# ATA5787 device description
Architecture: AVR8; Family: megaAVR
Registers are 8-bit, access not given, no defined reset value unless marked. A register's access mark holds for its fields unless they carry their own. Offsets are from the block's base; [hi:lo] are bit positions; {n}, {i} and the like mark numbered series.

## TIMER3
Instances: TIMER3 0x00
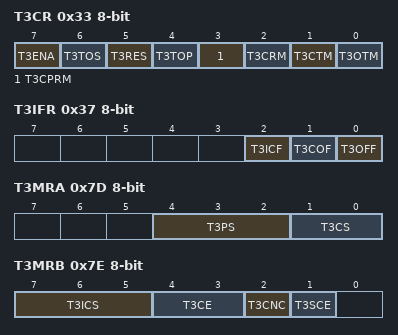
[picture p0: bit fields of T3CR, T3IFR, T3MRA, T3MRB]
0x33 T3CR — Timer3 Control Register
  [7] T3ENA — Timer3 Enable
  [6] T3TOS — Timer3 Toggle with Start
  [5] T3RES — Timer3 Reset
  [4] T3TOP — Timer3 Toggle Output Preset
  [3] T3CPRM — Timer3 Capture Reset Mask
  [2] T3CRM — Timer3 Compare Reset Mask
  [1] T3CTM — Timer3 Compare Toggle Mask
  [0] T3OTM — Timer3 Overflow Toggle Mask
0x37 T3IFR — Timer3 Interrupt Flag Register
  [2] T3ICF — Timer3 Input Capture Flag
  [1] T3COF — Timer3 Compare Flag
  [0] T3OFF — Timer3 Overflow Flag
0x77 T3CNT 16-bit — Timer3 Counter
0x79 T3COR 16-bit — Timer3 Compare
0x7B T3ICR 16-bit — Timer3 Input Capture
0x7D T3MRA — Timer3 Mode Register A
  [4:2] T3PS — Timer3 Prescaler Select
  [1:0] T3CS — Timer3 Clock Select
    0=CLK_FRC; 1=CLK_T; 2=CLK_XTO4; 3=CLK_XTO2
0x7E T3MRB — Timer3 Mode Register B
  [7:5] T3ICS — Timer3 Input Capture Select
    0=CLK_T2; 1=TRPA; 2=TRPB; 3=TICP; 4=CLK_SRC
  [4:3] T3CE — Timer3 Capture Edge Select
    0=DISABLE; 1=RISING_EDGE; 2=FALLING_EDGE; 3=BOTH_EDGES
  [2] T3CNC — Timer3 Input Capture Noise Canceller
  [1] T3SCE — Timer3 Software Capture Enable
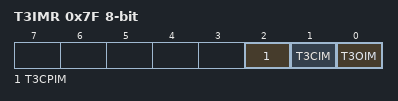
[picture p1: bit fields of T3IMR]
0x7F T3IMR — Timer3 Interrupt Mask Register
  [2] T3CPIM — Timer3 Capture Interrupt Mask
  [1] T3CIM — Timer3 Compare Interrupt Mask
  [0] T3OIM — Timer3 Overflow Interrupt Mask

## TIMER4
Instances: TIMER4 0x00
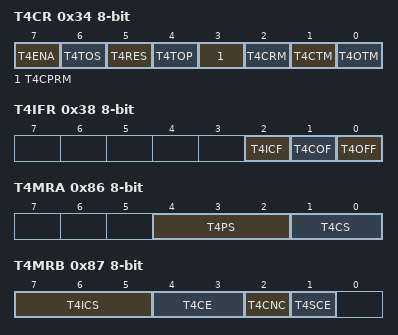
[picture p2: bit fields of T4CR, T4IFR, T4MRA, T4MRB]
0x34 T4CR — Timer4 Control Register
  [7] T4ENA — Timer4 Enable
  [6] T4TOS — Timer4 Toggle with Start
  [5] T4RES — Timer4 Reset
  [4] T4TOP — Timer4 Toggle Output Preset
  [3] T4CPRM — Timer4 Capture Reset Mask
  [2] T4CRM — Timer4 Compare Reset Mask
  [1] T4CTM — Timer4 Compare Toggle Mask
  [0] T4OTM — Timer4 Overflow Toggle Mask
0x38 T4IFR — Timer4 Interrupt Flag Register
  [2] T4ICF — Timer4 Input Capture Flag
  [1] T4COF — Timer4 Compare Flag
  [0] T4OFF — Timer4 Overflow Flag
0x80 T4CNT 16-bit — Timer4 Counter
0x82 T4COR 16-bit — Timer4 Compare
0x84 T4ICR 16-bit — Timer4 Input Capture
0x86 T4MRA — Timer4 Mode Register A
  [4:2] T4PS — Timer4 Prescaler Select
  [1:0] T4CS — Timer4 Clock Select
    0=CLK_SRC; 1=CLK_T; 2=CLK_XTO6; 3=CLK_FRC
0x87 T4MRB — Timer4 Mode Register B
  [7:5] T4ICS — Timer4 Input Capture Select
    0=CLK_T2; 1=TRPA; 2=TRPB; 3=TICP; 4=CLK_SRC
  [4:3] T4CE — Timer4 Capture Edge Select
    0=DISABLE; 1=RISING_EDGE; 2=FALLING_EDGE; 3=BOTH_EDGES
  [2] T4CNC — Timer4 Input Capture Noise Canceller
  [1] T4SCE — Timer4 Software Capture Enable
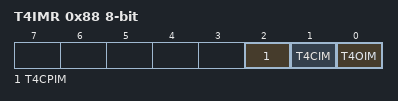
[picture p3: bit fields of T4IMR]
0x88 T4IMR — Timer4 Interrupt Mask Register
  [2] T4CPIM — Timer4 Capture Interrupt Mask
  [1] T4CIM — Timer4 Compare Interrupt Mask
  [0] T4OIM — Timer4 Overflow Interrupt Mask

## TIMER5
Instances: TIMER5 0x00
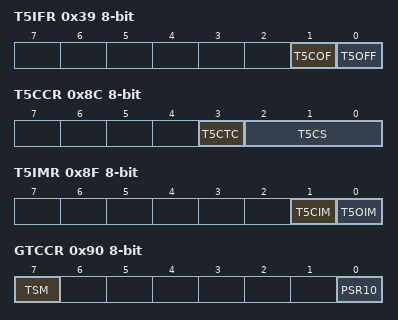
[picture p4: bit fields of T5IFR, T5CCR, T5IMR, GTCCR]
0x39 T5IFR — Timer5 Interrupt Flag Register
  [1] T5COF — Timer5 Compare Flag
  [0] T5OFF — Timer5 Overflow Flag
0x8A T5OCR 16-bit — Timer5 Output Compare
0x8C T5CCR — Timer5 Configuration and Control Register
  [3] T5CTC — Timer5 Clear Counter on Compare Match
  [2:0] T5CS — Timer5 Clock Select
    0=NO_CLOCK_SOURCE_STOPPED; 1=RUNNING_NO_PRESCALING; 2=RUNNING_CLK_8; 3=RUNNING_CLK_32; 4=RUNNING_CLK_64; 5=RUNNING_CLK_128; 6=RUNNING_CLK_256; 7=RUNNING_CLK_1024
0x8D T5CNT 16-bit — Timer5 Counter
0x8F T5IMR — Timer5 Interrupt Mask Register
  [1] T5CIM — Timer5 Compare Interrupt Mask
  [0] T5OIM — Timer5 Overflow Interrupt Mask
0x90 GTCCR — General Timer/Counter Control Register
  [7] TSM — Timer Synchronization Mode
  [0] PSR10 — Prescaler Reset

## TRACE
Instances: TRACE 0x00
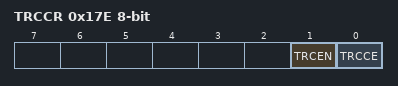
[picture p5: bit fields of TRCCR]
0x17E TRCCR — Trace Unit Control Register
  [1] TRCEN — Trace Unit Enable
  [0] TRCCE — Trace Unit Change Enable
0x17F TRCDR — Trace Unit Data Register
0x180 TRCID 16-bit — Trace Identifier

## VMON
Instances: VMON 0x00
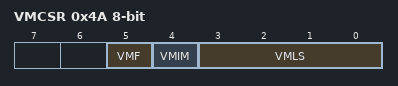
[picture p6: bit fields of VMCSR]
0x4A VMCSR — Voltage Monitor Control and Status Register
  [5] VMF — Voltage Monitor Flag
  [4] VMIM — Voltage Monitor Interrupt Mask
  [3:0] VMLS — Voltage Monitor Level Select
    0=DISABLE; {v}=2_{v-1}V (v=1..10); {v}=3_{v-11}V (v=11..15)
